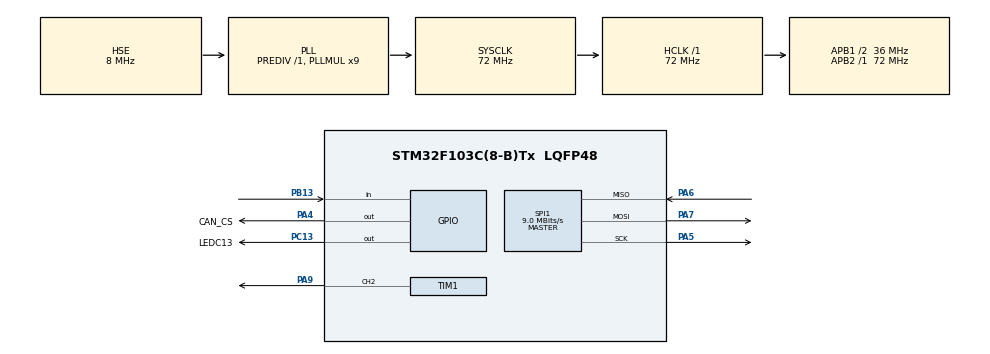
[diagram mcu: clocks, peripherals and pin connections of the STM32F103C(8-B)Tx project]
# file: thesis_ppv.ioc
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Mcu.Family=STM32F1
Mcu.Name=STM32F103C(8-B)Tx
Mcu.Package=LQFP48
NVIC.PriorityGroup=NVIC_PRIORITYGROUP_4
NVIC.TIM2_IRQn=true\:0\:0\:false\:false\:true\:true\:true
PA13.Mode=Serial_Wire
PA13.Signal=SYS_JTMS-SWDIO
PA14.Mode=Serial_Wire
PA14.Signal=SYS_JTCK-SWCLK
PA4.GPIO_Label=CAN_CS
PA4.GPIO_Speed=GPIO_SPEED_FREQ_MEDIUM
PA4.PinState=GPIO_PIN_SET
PA4.Signal=GPIO_Output
PA5.Mode=Full_Duplex_Master
PA5.Signal=SPI1_SCK
PA6.Mode=Full_Duplex_Master
PA6.Signal=SPI1_MISO
PA7.Mode=Full_Duplex_Master
PA7.Signal=SPI1_MOSI
PA9.Signal=S_TIM1_CH2
PB13.GPIO_PuPd=GPIO_PULLDOWN
PB13.Signal=GPIO_Input
PC13-TAMPER-RTC.GPIO_Label=LEDC13
PC13-TAMPER-RTC.Signal=GPIO_Output
PD0-OSC_IN.Mode=HSE-External-Oscillator
PD0-OSC_IN.Signal=RCC_OSC_IN
PD1-OSC_OUT.Mode=HSE-External-Oscillator
PD1-OSC_OUT.Signal=RCC_OSC_OUT
ProjectManager.HeapSize=0x200
ProjectManager.StackSize=0x400
ProjectManager.TargetToolchain=STM32CubeIDE
RCC.AHBFreq_Value=72000000
RCC.APB1CLKDivider=RCC_HCLK_DIV2
RCC.APB1Freq_Value=36000000
RCC.APB1TimFreq_Value=72000000
RCC.APB2Freq_Value=72000000
RCC.APB2TimFreq_Value=72000000
RCC.HCLKFreq_Value=72000000
RCC.PLLMUL=RCC_PLL_MUL9
RCC.PLLSourceVirtual=RCC_PLLSOURCE_HSE
RCC.SYSCLKFreq_VALUE=72000000
RCC.SYSCLKSource=RCC_SYSCLKSOURCE_PLLCLK
RCC.USBFreq_Value=72000000
SH.S_TIM1_CH2.0=TIM1_CH2,PWM Generation2 CH2
SPI1.BaudRatePrescaler=SPI_BAUDRATEPRESCALER_8
SPI1.CalculateBaudRate=9.0 MBits/s
SPI1.Direction=SPI_DIRECTION_2LINES
SPI1.Mode=SPI_MODE_MASTER
SPI1.VirtualType=VM_MASTER
TIM1.Channel-PWM\ Generation2\ CH2=TIM_CHANNEL_2
TIM1.Period=9999
TIM1.Prescaler=71
TIM2.Period=71
TIM2.Prescaler=9999
VP_TIM2_VS_ClockSourceINT.Mode=Internal
board=custom

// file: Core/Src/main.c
/* USER CODE BEGIN Header */
/**
  ******************************************************************************
  * @file           : main.c
  * @brief          : Main program body
  ******************************************************************************
  * @attention
  *
  * <h2><center>&copy; Copyright (c) 2024 STMicroelectronics.
  * All rights reserved.</center></h2>
  *
  * This software component is licensed by ST under BSD 3-Clause license,
  * the "License"; You may not use this file except in compliance with the
  * License. You may obtain a copy of the License at:
  *                        opensource.org/licenses/BSD-3-Clause
  *
  ******************************************************************************
  */
/* USER CODE END Header */
#include "main.h"

/* USER CODE BEGIN Includes */
#include "CANSPI.h"
#include "MCP2515.h"
#include "CAN_processing.h"
#include "software_timer.h"
/* USER CODE END Includes */

SPI_HandleTypeDef hspi1;

TIM_HandleTypeDef htim1;
TIM_HandleTypeDef htim2;

void SystemClock_Config(void);
static void MX_GPIO_Init(void);
static void MX_SPI1_Init(void);
static void MX_TIM2_Init(void);
static void MX_TIM1_Init(void);

int main(void)
{

  /* MCU Configuration--------------------------------------------------------*/

  /* Reset of all peripherals, Initializes the Flash interface and the Systick. */
  HAL_Init();

  /* Configure the system clock */
  SystemClock_Config();

  /* Initialize all configured peripherals */
  MX_GPIO_Init();
  MX_SPI1_Init();
  MX_TIM2_Init();
  MX_TIM1_Init();
  /* USER CODE BEGIN 2 */
  HAL_TIM_Base_Start_IT(&htim2);
  HAL_TIM_PWM_Start(&htim1, TIM_CHANNEL_2);
  /* USER CODE END 2 */

  /* Infinite loop */
  /* USER CODE BEGIN WHILE */

  CAN_Init();
  LED_pwm_Init();
  while (1)
  {
    /* USER CODE END WHILE */

    /* USER CODE BEGIN 3 */
	CAN_Processing();
	HAL_Delay(50);
  }
  /* USER CODE END 3 */
}

void SystemClock_Config(void)
{
  RCC_OscInitTypeDef RCC_OscInitStruct = {0};
  RCC_ClkInitTypeDef RCC_ClkInitStruct = {0};

  /** Initializes the RCC Oscillators according to the specified parameters
  * in the RCC_OscInitTypeDef structure.
  */
  RCC_OscInitStruct.OscillatorType = RCC_OSCILLATORTYPE_HSE;
  RCC_OscInitStruct.HSEState = RCC_HSE_ON;
  RCC_OscInitStruct.HSEPredivValue = RCC_HSE_PREDIV_DIV1;
  RCC_OscInitStruct.HSIState = RCC_HSI_ON;
  RCC_OscInitStruct.PLL.PLLState = RCC_PLL_ON;
  RCC_OscInitStruct.PLL.PLLSource = RCC_PLLSOURCE_HSE;
  RCC_OscInitStruct.PLL.PLLMUL = RCC_PLL_MUL9;
  if (HAL_RCC_OscConfig(&RCC_OscInitStruct) != HAL_OK)
  {
    Error_Handler();
  }
  /** Initializes the CPU, AHB and APB buses clocks
  */
  RCC_ClkInitStruct.ClockType = RCC_CLOCKTYPE_HCLK|RCC_CLOCKTYPE_SYSCLK
                              |RCC_CLOCKTYPE_PCLK1|RCC_CLOCKTYPE_PCLK2;
  RCC_ClkInitStruct.SYSCLKSource = RCC_SYSCLKSOURCE_PLLCLK;
  RCC_ClkInitStruct.AHBCLKDivider = RCC_SYSCLK_DIV1;
  RCC_ClkInitStruct.APB1CLKDivider = RCC_HCLK_DIV2;
  RCC_ClkInitStruct.APB2CLKDivider = RCC_HCLK_DIV1;

  if (HAL_RCC_ClockConfig(&RCC_ClkInitStruct, FLASH_LATENCY_2) != HAL_OK)
  {
    Error_Handler();
  }
}

static void MX_SPI1_Init(void)
{

  /* SPI1 parameter configuration*/
  hspi1.Instance = SPI1;
  hspi1.Init.Mode = SPI_MODE_MASTER;
  hspi1.Init.Direction = SPI_DIRECTION_2LINES;
  hspi1.Init.DataSize = SPI_DATASIZE_8BIT;
  hspi1.Init.CLKPolarity = SPI_POLARITY_LOW;
  hspi1.Init.CLKPhase = SPI_PHASE_1EDGE;
  hspi1.Init.NSS = SPI_NSS_SOFT;
  hspi1.Init.BaudRatePrescaler = SPI_BAUDRATEPRESCALER_8;
  hspi1.Init.FirstBit = SPI_FIRSTBIT_MSB;
  hspi1.Init.TIMode = SPI_TIMODE_DISABLE;
  hspi1.Init.CRCCalculation = SPI_CRCCALCULATION_DISABLE;
  hspi1.Init.CRCPolynomial = 10;
  if (HAL_SPI_Init(&hspi1) != HAL_OK)
  {
    Error_Handler();
  }

}

static void MX_TIM1_Init(void)
{

  TIM_MasterConfigTypeDef sMasterConfig = {0};
  TIM_OC_InitTypeDef sConfigOC = {0};
  TIM_BreakDeadTimeConfigTypeDef sBreakDeadTimeConfig = {0};

  htim1.Instance = TIM1;
  htim1.Init.Prescaler = 71;
  htim1.Init.CounterMode = TIM_COUNTERMODE_UP;
  htim1.Init.Period = 9999;
  htim1.Init.ClockDivision = TIM_CLOCKDIVISION_DIV1;
  htim1.Init.RepetitionCounter = 0;
  htim1.Init.AutoReloadPreload = TIM_AUTORELOAD_PRELOAD_DISABLE;
  if (HAL_TIM_PWM_Init(&htim1) != HAL_OK)
  {
    Error_Handler();
  }
  sMasterConfig.MasterOutputTrigger = TIM_TRGO_RESET;
  sMasterConfig.MasterSlaveMode = TIM_MASTERSLAVEMODE_DISABLE;
  if (HAL_TIMEx_MasterConfigSynchronization(&htim1, &sMasterConfig) != HAL_OK)
  {
    Error_Handler();
  }
  sConfigOC.OCMode = TIM_OCMODE_PWM1;
  sConfigOC.Pulse = 0;
  sConfigOC.OCPolarity = TIM_OCPOLARITY_HIGH;
  sConfigOC.OCNPolarity = TIM_OCNPOLARITY_HIGH;
  sConfigOC.OCFastMode = TIM_OCFAST_DISABLE;
  sConfigOC.OCIdleState = TIM_OCIDLESTATE_RESET;
  sConfigOC.OCNIdleState = TIM_OCNIDLESTATE_RESET;
  if (HAL_TIM_PWM_ConfigChannel(&htim1, &sConfigOC, TIM_CHANNEL_2) != HAL_OK)
  {
    Error_Handler();
  }
  sBreakDeadTimeConfig.OffStateRunMode = TIM_OSSR_DISABLE;
  sBreakDeadTimeConfig.OffStateIDLEMode = TIM_OSSI_DISABLE;
  sBreakDeadTimeConfig.LockLevel = TIM_LOCKLEVEL_OFF;
  sBreakDeadTimeConfig.DeadTime = 0;
  sBreakDeadTimeConfig.BreakState = TIM_BREAK_DISABLE;
  sBreakDeadTimeConfig.BreakPolarity = TIM_BREAKPOLARITY_HIGH;
  sBreakDeadTimeConfig.AutomaticOutput = TIM_AUTOMATICOUTPUT_DISABLE;
  if (HAL_TIMEx_ConfigBreakDeadTime(&htim1, &sBreakDeadTimeConfig) != HAL_OK)
  {
    Error_Handler();
  }
  HAL_TIM_MspPostInit(&htim1);

}

static void MX_TIM2_Init(void)
{

  TIM_ClockConfigTypeDef sClockSourceConfig = {0};
  TIM_MasterConfigTypeDef sMasterConfig = {0};

  htim2.Instance = TIM2;
  htim2.Init.Prescaler = 9999;
  htim2.Init.CounterMode = TIM_COUNTERMODE_UP;
  htim2.Init.Period = 71;
  htim2.Init.ClockDivision = TIM_CLOCKDIVISION_DIV1;
  htim2.Init.AutoReloadPreload = TIM_AUTORELOAD_PRELOAD_DISABLE;
  if (HAL_TIM_Base_Init(&htim2) != HAL_OK)
  {
    Error_Handler();
  }
  sClockSourceConfig.ClockSource = TIM_CLOCKSOURCE_INTERNAL;
  if (HAL_TIM_ConfigClockSource(&htim2, &sClockSourceConfig) != HAL_OK)
  {
    Error_Handler();
  }
  sMasterConfig.MasterOutputTrigger = TIM_TRGO_RESET;
  sMasterConfig.MasterSlaveMode = TIM_MASTERSLAVEMODE_DISABLE;
  if (HAL_TIMEx_MasterConfigSynchronization(&htim2, &sMasterConfig) != HAL_OK)
  {
    Error_Handler();
  }

}

static void MX_GPIO_Init(void)
{
  GPIO_InitTypeDef GPIO_InitStruct = {0};

  /* GPIO Ports Clock Enable */
  __HAL_RCC_GPIOC_CLK_ENABLE();
  __HAL_RCC_GPIOD_CLK_ENABLE();
  __HAL_RCC_GPIOA_CLK_ENABLE();
  __HAL_RCC_GPIOB_CLK_ENABLE();

  /*Configure GPIO pin Output Level */
  HAL_GPIO_WritePin(LEDC13_GPIO_Port, LEDC13_Pin, GPIO_PIN_RESET);

  /*Configure GPIO pin Output Level */
  HAL_GPIO_WritePin(CAN_CS_GPIO_Port, CAN_CS_Pin, GPIO_PIN_SET);

  /*Configure GPIO pin : LEDC13_Pin */
  GPIO_InitStruct.Pin = LEDC13_Pin;
  GPIO_InitStruct.Mode = GPIO_MODE_OUTPUT_PP;
  GPIO_InitStruct.Pull = GPIO_NOPULL;
  GPIO_InitStruct.Speed = GPIO_SPEED_FREQ_LOW;
  HAL_GPIO_Init(LEDC13_GPIO_Port, &GPIO_InitStruct);

  /*Configure GPIO pin : CAN_CS_Pin */
  GPIO_InitStruct.Pin = CAN_CS_Pin;
  GPIO_InitStruct.Mode = GPIO_MODE_OUTPUT_PP;
  GPIO_InitStruct.Pull = GPIO_NOPULL;
  GPIO_InitStruct.Speed = GPIO_SPEED_FREQ_MEDIUM;
  HAL_GPIO_Init(CAN_CS_GPIO_Port, &GPIO_InitStruct);

  /*Configure GPIO pin : PB13 */
  GPIO_InitStruct.Pin = GPIO_PIN_13;
  GPIO_InitStruct.Mode = GPIO_MODE_INPUT;
  GPIO_InitStruct.Pull = GPIO_PULLDOWN;
  HAL_GPIO_Init(GPIOB, &GPIO_InitStruct);

}

/* USER CODE BEGIN 4 */
void HAL_TIM_PeriodElapsedCallback(TIM_HandleTypeDef *htim)
{
	timerRun();
}
/* USER CODE END 4 */

void Error_Handler(void)
{
  __disable_irq();
  while (1)
  {
  }
}

/************************ (C) COPYRIGHT STMicroelectronics *****END OF FILE****/
